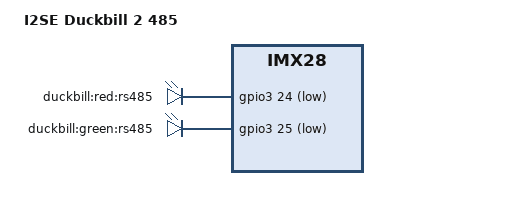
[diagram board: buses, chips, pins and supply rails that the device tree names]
// SPDX-License-Identifier: GPL-2.0-or-later
/*
 * Copyright (C) 2015-2017 I2SE GmbH <info@i2se.com>
 * Copyright (C) 2016 Michael Heimpold <mhei@heimpold.de>
 */

/dts-v1/;
#include "imx28-duckbill-2.dts"

/ {
	model = "I2SE Duckbill 2 485";
	compatible = "i2se,duckbill-2-485", "i2se,duckbill-2", "fsl,imx28";

	leds {
		rs485-red {
			label = "duckbill:red:rs485";
			gpios = <&gpio3 24 GPIO_ACTIVE_LOW>;
		};

		rs485-green {
			label = "duckbill:green:rs485";
			gpios = <&gpio3 25 GPIO_ACTIVE_LOW>;
		};
	};
};

&i2c0 {
	status = "disabled";
};

&led_pins {
	fsl,pinmux-ids = <
		MX28_PAD_SAIF0_MCLK__GPIO_3_20
		MX28_PAD_SAIF0_LRCLK__GPIO_3_21
		MX28_PAD_I2C0_SCL__GPIO_3_24
		MX28_PAD_I2C0_SDA__GPIO_3_25
	>;
};
